AUTOSAR XML (schema 4-0-3)
standard types defined: Boolean, UInt32
package /AUTOSAR_Platform/DataConstrs
  range DC_Boolean: raw 0..1
package /PATAC/MSM/ComponentTypes
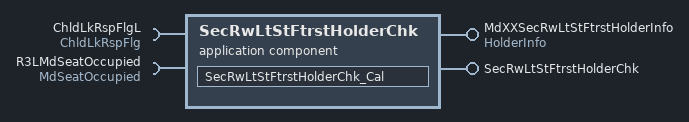
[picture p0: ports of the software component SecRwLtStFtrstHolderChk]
  application sw component type SecRwLtStFtrstHolderChk
    provide port MdXXSecRwLtStFtrstHolderInfo: nonqueued-sender-com-spec{data-element=HolderInfo/Val, init-value=0}, provided-interface=HolderInfo
    provide port SecRwLtStFtrstHolderChk: server-com-spec{operation=Cal, queue-length=1}, provided-interface=SecRwLtStFtrstHolderChk
    require port ChldLkRspFlgL: nonqueued-receiver-com-spec{data-element=ChldLkRspFlg/Val, filter=data-filter-type=ALWAYS, init-value=0}, required-interface=ChldLkRspFlg
    require port R3LMdSeatOccupied: nonqueued-receiver-com-spec{data-element=MdSeatOccupied/Val, filter=data-filter-type=ALWAYS, init-value=0}, required-interface=MdSeatOccupied
    behavior SecRwLtStFtrstHolderChk_InternalBehavior
      operation invoked event OIT_SecRwLtStFtrstHolderChk_Cal_SecRwLtStFtrstHolderChk_Cal: start-on-event=SecRwLtStFtrstHolderChk_Cal, operation=SecRwLtStFtrstHolderChk.Cal
      runnable SecRwLtStFtrstHolderChk_Cal
        data-receive-point-by-arguments:
          access REC_ChldLkRspFlgL_Val: accessed-variable=ChldLkRspFlgL.Val
          access REC_R3LMdSeatOccupied_Val: accessed-variable=R3LMdSeatOccupied.Val
        data-send-points:
          access SEND_MdXXSecRwLtStFtrstHolderInfo_Val: accessed-variable=MdXXSecRwLtStFtrstHolderInfo.Val
  swc implementation SecRwLtStFtrstHolderChk_Implementation: behavior=SecRwLtStFtrstHolderChk_InternalBehavior
    code-descriptors:
      code Default: artifact-descriptors=autosar-engineering-object={short-label=Default, category=SWSRC}
package /PATAC/MSM/ModeAdjust/PortInterface
  client server interface SecRwLtStFtrstHolderChk
    operation Cal
  sender receiver interface ChldLkRspFlg: invalidation-policy{data-element=ChldLkRspFlg/Val, handle-invalid=DONT-INVALIDATE}
    data Val: type=Boolean
  sender receiver interface HolderInfo: invalidation-policy{data-element=HolderInfo/Val, handle-invalid=DONT-INVALIDATE}
    data Val: type=UInt32
  sender receiver interface MdSeatOccupied: invalidation-policy{data-element=MdSeatOccupied/Val, handle-invalid=DONT-INVALIDATE}
    data Val: type=Boolean
